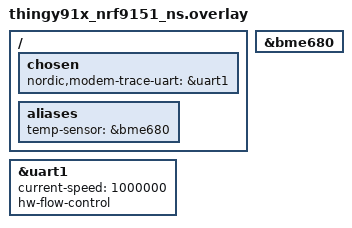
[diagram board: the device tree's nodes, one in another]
/*
 * Copyright (c) 2024 Nordic Semiconductor ASA
 *
 * SPDX-License-Identifier: LicenseRef-Nordic-5-Clause
 */

/* Enable uart1 for tracing. */
&uart1 {
	status = "okay";
	current-speed = < 1000000 >;
	hw-flow-control;
};

/ {
	chosen {
		nordic,modem-trace-uart = &uart1;
	};
};

/ {
	aliases {
		temp-sensor = &bme680;
	};
};

&bme680 {
	status = "okay";
};
